# iospear320 register map
Registers are 32-bit, access not given, no defined reset value unless marked. A register's access mark holds for its fields unless they carry their own. Addresses are absolute; registers are grouped by the start of their names; [hi:lo] are bit positions; {n}, {i} and the like mark numbered series; 'fields as' and 'values as' point back to an identical list.

## MACB3
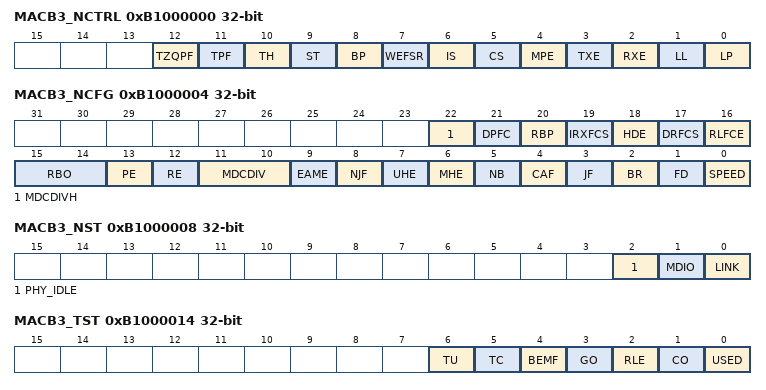
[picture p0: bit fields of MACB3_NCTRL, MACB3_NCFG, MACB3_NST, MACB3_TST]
0xB1000000 MACB3_NCTRL
  [12] TZQPF, [11] TPF, [10] TH, [9] ST, [8] BP, [7] WEFSR, [6] IS, [5] CS, [4] MPE, [3] TXE, [2] RXE, [1] LL, [0] LP
0xB1000004 MACB3_NCFG
  [22] MDCDIVH, [21] DPFC, [20] RBP, [19] IRXFCS, [18] HDE, [17] DRFCS, [16] RLFCE, [15:14] RBO, [13] PE, [12] RE, [11:10] MDCDIV, [9] EAME, [8] NJF, [7] UHE, [6] MHE, [5] NB, [4] CAF, [3] JF, [2] BR, [1] FD, [0] SPEED
0xB1000008 MACB3_NST
  [2] PHY_IDLE, [1] MDIO, [0] LINK
0xB1000014 MACB3_TST
  [6] TU, [5] TC, [4] BEMF, [3] GO, [2] RLE, [1] CO, [0] USED
0xB1000018 MACB3_RBQP
0xB100001C MACB3_TBQP
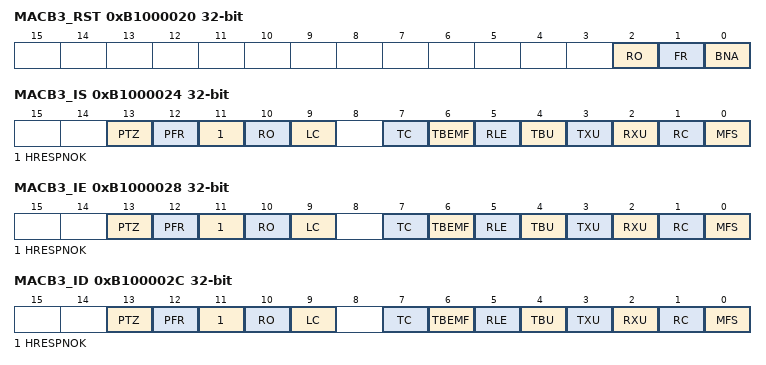
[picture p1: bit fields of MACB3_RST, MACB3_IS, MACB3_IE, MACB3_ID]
0xB1000020 MACB3_RST
  [2] RO, [1] FR, [0] BNA
0xB1000024 MACB3_IS
  [13] PTZ, [12] PFR, [11] HRESPNOK, [10] RO, [9] LC, [7] TC, [6] TBEMF, [5] RLE, [4] TBU, [3] TXU, [2] RXU, [1] RC, [0] MFS
0xB1000028 MACB3_IE
  fields as MACB3_IS
0xB100002C MACB3_ID
  fields as MACB3_IS
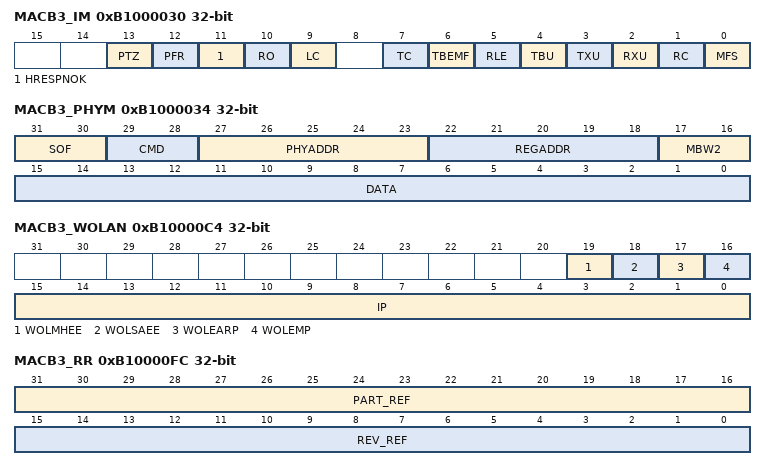
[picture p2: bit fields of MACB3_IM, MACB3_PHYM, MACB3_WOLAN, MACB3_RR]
0xB1000030 MACB3_IM
  fields as MACB3_IS
0xB1000034 MACB3_PHYM
  [31:30] SOF, [29:28] CMD, [27:23] PHYADDR, [22:18] REGADDR, [17:16] MBW2, [15:0] DATA
0xB1000038 MACB3_PT
  [15:0] PT
0xB100003C MACB3_PFR
  [15:0] FRAME_CNTR
0xB1000040 MACB3_FT
  [15:0] FRAME_CNTR
0xB1000044 MACB3_SCF
  [15:0] FRAME_CNTR
0xB1000048 MACB3_MCF
  [15:0] FRAME_CNTR
0xB100004C MACB3_FR
  [23:0] FRAME_CNTR
0xB1000050 MACB3_FCSE
  [7:0] FCSE
0xB1000054 MACB3_AE
  [7:0] AE
0xB1000058 MACB3_DTF
  [15:0] DTF
0xB100005C MACB3_LC
  [7:0] LC
0xB1000060 MACB3_EC
  [7:0] EC
0xB1000064 MACB3_TUE
  [7:0] TUE
0xB1000068 MACB3_CSE
  [7:0] CSE
0xB100006C MACB3_RRE
  [15:0] RRE
0xB1000070 MACB3_ROE
  [7:0] ROE
0xB1000074 MACB3_RSE
  [7:0] REE
0xB1000078 MACB3_ELE
  [7:0] ELE
0xB100007C MACB3_RJ
  [7:0] RJ
0xB1000080 MACB3_UF
  [7:0] UF
0xB1000084 MACB3_SEQTE
  [7:0] SQETE
0xB1000088 MACB3_RLFM
  [7:0] RLFM
0xB100008C MACB3_TPF
  [15:0] TPF
0xB1000090 MACB3_HRB
0xB1000094 MACB3_HRT
{0xB1000090+8i} MACB3_SAB{i} (i=1..4)
{0xB1000094+8i} MACB3_SAT{i} (i=1..4)
  [15:0] ADDR
0xB10000B8 MACB3_TIDC
  [15:0] ID
0xB10000BC MACB3_TPQ
  [15:0] TPQ
0xB10000C4 MACB3_WOLAN
  [19] WOLMHEE, [18] WOLSAEE, [17] WOLEARP, [16] WOLEMP, [15:0] IP
0xB10000FC MACB3_RR
  [31:16] PART_REF, [15:0] REV_REF

## MACB4
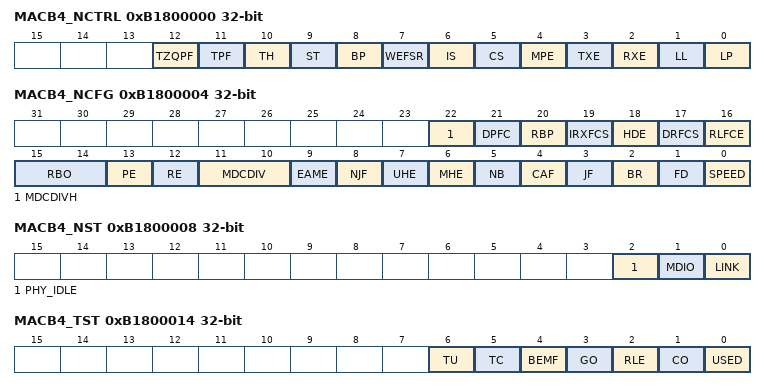
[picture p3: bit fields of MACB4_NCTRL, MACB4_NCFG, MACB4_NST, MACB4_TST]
0xB1800000 MACB4_NCTRL
  [12] TZQPF, [11] TPF, [10] TH, [9] ST, [8] BP, [7] WEFSR, [6] IS, [5] CS, [4] MPE, [3] TXE, [2] RXE, [1] LL, [0] LP
0xB1800004 MACB4_NCFG
  [22] MDCDIVH, [21] DPFC, [20] RBP, [19] IRXFCS, [18] HDE, [17] DRFCS, [16] RLFCE, [15:14] RBO, [13] PE, [12] RE, [11:10] MDCDIV, [9] EAME, [8] NJF, [7] UHE, [6] MHE, [5] NB, [4] CAF, [3] JF, [2] BR, [1] FD, [0] SPEED
0xB1800008 MACB4_NST
  [2] PHY_IDLE, [1] MDIO, [0] LINK
0xB1800014 MACB4_TST
  [6] TU, [5] TC, [4] BEMF, [3] GO, [2] RLE, [1] CO, [0] USED
0xB1800018 MACB4_RBQP
0xB180001C MACB4_TBQP
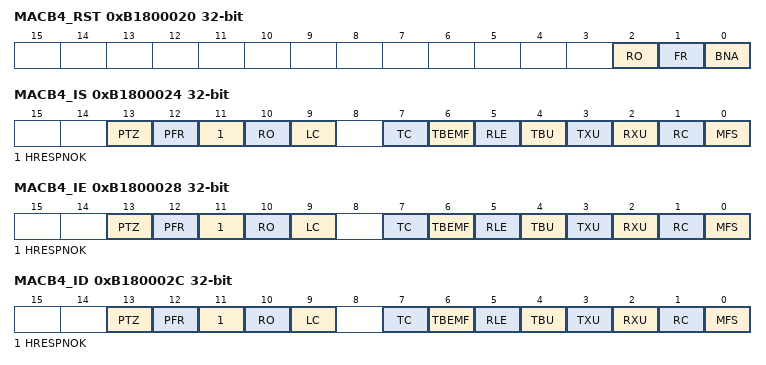
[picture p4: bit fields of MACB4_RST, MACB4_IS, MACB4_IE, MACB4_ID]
0xB1800020 MACB4_RST
  [2] RO, [1] FR, [0] BNA
0xB1800024 MACB4_IS
  [13] PTZ, [12] PFR, [11] HRESPNOK, [10] RO, [9] LC, [7] TC, [6] TBEMF, [5] RLE, [4] TBU, [3] TXU, [2] RXU, [1] RC, [0] MFS
0xB1800028 MACB4_IE
  fields as MACB4_IS
0xB180002C MACB4_ID
  fields as MACB4_IS
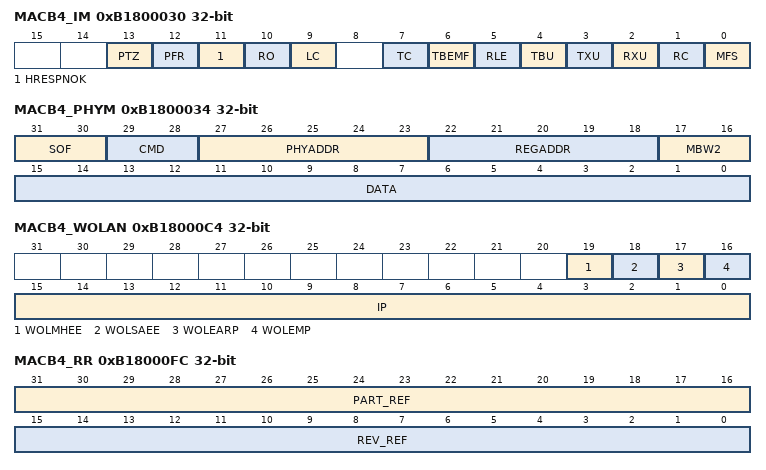
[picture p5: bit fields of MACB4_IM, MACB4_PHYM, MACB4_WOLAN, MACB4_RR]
0xB1800030 MACB4_IM
  fields as MACB4_IS
0xB1800034 MACB4_PHYM
  [31:30] SOF, [29:28] CMD, [27:23] PHYADDR, [22:18] REGADDR, [17:16] MBW2, [15:0] DATA
0xB1800038 MACB4_PT
  [15:0] PT
0xB180003C MACB4_PFR
  [15:0] FRAME_CNTR
0xB1800040 MACB4_FT
  [15:0] FRAME_CNTR
0xB1800044 MACB4_SCF
  [15:0] FRAME_CNTR
0xB1800048 MACB4_MCF
  [15:0] FRAME_CNTR
0xB180004C MACB4_FR
  [23:0] FRAME_CNTR
0xB1800050 MACB4_FCSE
  [7:0] FCSE
0xB1800054 MACB4_AE
  [7:0] AE
0xB1800058 MACB4_DTF
  [15:0] DTF
0xB180005C MACB4_LC
  [7:0] LC
0xB1800060 MACB4_EC
  [7:0] EC
0xB1800064 MACB4_TUE
  [7:0] TUE
0xB1800068 MACB4_CSE
  [7:0] CSE
0xB180006C MACB4_RRE
  [15:0] RRE
0xB1800070 MACB4_ROE
  [7:0] ROE
0xB1800074 MACB4_RSE
  [7:0] REE
0xB1800078 MACB4_ELE
  [7:0] ELE
0xB180007C MACB4_RJ
  [7:0] RJ
0xB1800080 MACB4_UF
  [7:0] UF
0xB1800084 MACB4_SEQTE
  [7:0] SQETE
0xB1800088 MACB4_RLFM
  [7:0] RLFM
0xB180008C MACB4_TPF
  [15:0] TPF
0xB1800090 MACB4_HRB
0xB1800094 MACB4_HRT
{0xB1800090+8i} MACB4_SAB{i} (i=1..4)
{0xB1800094+8i} MACB4_SAT{i} (i=1..4)
  [15:0] ADDR
0xB18000B8 MACB4_TIDC
  [15:0] ID
0xB18000BC MACB4_TPQ
  [15:0] TPQ
0xB18000C4 MACB4_WOLAN
  [19] WOLMHEE, [18] WOLSAEE, [17] WOLEARP, [16] WOLEMP, [15:0] IP
0xB18000FC MACB4_RR
  [31:16] PART_REF, [15:0] REV_REF
